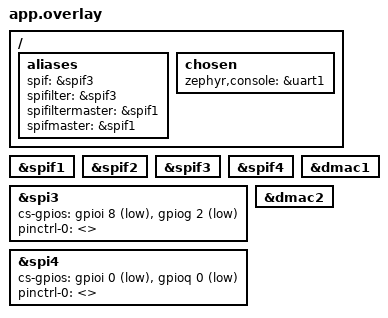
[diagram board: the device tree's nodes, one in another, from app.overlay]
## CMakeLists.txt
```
# SPDX-License-Identifier: Apache-2.0

cmake_minimum_required(VERSION 3.20.0)

# ---------------------------------------------------------------------------
# pfr_tpm 模块注册。
# zephyr/west.yml **并未**注册该模块（`west list` 无此项）。
# app.overlay 的 "lsqsh_pinctrl_pfr_tpm.dtsi" 必须靠这里就地注册，
# 否则 DT 预处理直接失败："fatal error: lsqsh_pinctrl_pfr_tpm.dtsi: No such file or directory"。
# 模块目录在两种工作区里命名不同（zephyr_pfr_tpm / pfr_tpm），按存在者取；
# 旧版本写死 d:/zephyr4_0/... 换工作区/WSL 会失效，故改为相对路径推算
# （CMAKE_CURRENT_SOURCE_DIR 上溯 4 级 = 工作区根）。必须在 find_package(Zephyr) 之前 set。
# ---------------------------------------------------------------------------
get_filename_component(PFR_TPM_WS "${CMAKE_CURRENT_SOURCE_DIR}/../../../.." ABSOLUTE)
if(EXISTS "${PFR_TPM_WS}/modules/lib/zephyr_pfr_tpm/zephyr/module.yml")
  set(PFR_TPM_DIR "${PFR_TPM_WS}/modules/lib/zephyr_pfr_tpm")
elseif(EXISTS "${PFR_TPM_WS}/modules/lib/pfr_tpm/zephyr/module.yml")
  set(PFR_TPM_DIR "${PFR_TPM_WS}/modules/lib/pfr_tpm")
else()
  message(FATAL_ERROR "pfr_tpm module not found under ${PFR_TPM_WS}/modules/lib")
endif()
set(EXTRA_ZEPHYR_MODULES ${PFR_TPM_DIR})

find_package(Zephyr REQUIRED HINTS $ENV{ZEPHYR_BASE})
project(cpu1_spif_test)

# 项目特定源文件
target_sources(app PRIVATE
    src/main.c
    src/spif_test.c
    src/spif_loopback.c)

# 项目特定 include 目录
target_include_directories(app PRIVATE
    ${CMAKE_CURRENT_SOURCE_DIR}/../tests/include)

# 包含公共源文件和配置（test_results.c, ztest_glue.c, gpio_toggle.c）
include(${CMAKE_CURRENT_SOURCE_DIR}/../../../common/common_sources.cmake)
```

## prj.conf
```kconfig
# SPDX-License-Identifier: Apache-2.0
#
# spif_test 单核 cpu1 固件配置（SPEC_REFERENCE §6.1.7 / §6.1.8）。

# ---- log 规范（§6.1.7）：统一 LOG_INF，buf 模式异步输出 ----
CONFIG_LOG=y
CONFIG_LOG_MODE_DEFERRED=y
CONFIG_LOG_BUFFER_SIZE=16384
CONFIG_LOG_PROCESS_THREAD_SLEEP_MS=10
CONFIG_LOG_BACKEND_UART=y
CONFIG_LOG_PRINTK=n
CONFIG_SERIAL=y
CONFIG_SHELL=n

# ---- ztest（§6.2.1）：逐项输出必须打开 ----
CONFIG_ZTEST=y
CONFIG_ZTEST_ASSERT_VERBOSE=1
CONFIG_ZTEST_VERBOSE_OUTPUT=y
CONFIG_ZTEST_SUMMARY=n

# ---- libc 三件套（§10.35 / KNOWN_ISSUES #58）----
CONFIG_PICOLIBC=y
CONFIG_NEWLIB_LIBC=n
CONFIG_MINIMAL_LIBC=n

# ---- GPIO toggle 线程（公共层 gpio_toggle.c 依赖）----
CONFIG_GPIO=y

# ---- 被测驱动：pfr_tpm spi filter ----
# CONFIG_SPI_FILTER_LINKEDSEMI 默认 y（depends on DT_HAS_LINKEDSEMI_SPI_FILTER_ENABLED），
# 且 select SPI / select DMA；CONFIG_PFR_TPM_LINKER_LD 随之 default y
# （模块 common/linker.ld 把各实例的白名单镜像放 PFR_TPM 段，本工程依赖该段）。
CONFIG_SPI=y
CONFIG_SPI_FILTER_LINKEDSEMI=y
CONFIG_DMA=y
```

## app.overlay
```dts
/*
 * SPDX-License-Identifier: Apache-2.0
 *
 * spif_test overlay（单核 cpu1 安全域）：使能 SPIF1..4（SPI filter / monitor）
 * 以及它们配对的 SPI master 控制器（spi1/spif1 用 spi3；spif3/spif4 用 spi4）。
 *
 * 外部条件（SPEC_REFERENCE §6.6）：
 *   - SPIF 的 "in 侧" 管脚（滤波/监视模式的输入，以及 master 模式下 SPI 主控
 *     的 CLK/IO0..3/CSN 输出）在板级连到 **spi3 / spi4 上挂的 flash**。
 *     本工程 master 模式用例（`master_read_jedec_id`）走这条外部路径。
 *   - 其余寄存器级用例零外部条件。
 *
 * ⚠️ 配对控制器必须让渡引脚（P4.7 裁定，依据参考资产 spi_master_communication /
 *    spi_monitor_filter 的 overlay，二者在实机跑通）：
 *    SPIF 切 master 模式走的是 **SPIF 自己的 `pinctrl-2`(master 态)** 管脚
 *    （如 spif3 → PF09/PF05/PF03/PF11/PF07 + CSN PI00），而配对的 DW SPI 控制器
 *    默认仍持板级 pinctrl（spi3 → PG14/PG15/PG03/PE01/PE00；spi4 → PQ00/PQ03…）。
 *    两组管脚不同 ⇒ 不清空配对控制器的 `pinctrl-0` 就是"两个 owner 抢一组 net"，
 *    真实总线由谁驱动不确定。故此处显式清空。
 *    （同型问题见 gotchas G-P4-4「配对 I2C 控制器 pinctrl-noinit」/ G-P4.7-1。）
 */

#include "lsqsh_pinctrl_pfr_tpm.dtsi"

/ {
	aliases {
		/* 回环路径：spif1 发命令/数据，spif3 作 filter/passthrough 监视。
		 * spifmaster/spifiltermaster 都指向 spif1；spif/spifilter 指向 spif3。
		 * 旧的 spifmaster=&spif3 是 spif3-master 用例遗留，已纠正。 */
		spif = &spif3;
		spifilter = &spif3;
		spifiltermaster = &spif1;
		spifmaster = &spif1;
	};

	chosen {
		zephyr,console = &uart1;
	};
};

&spif1 {
	status = "okay";
};

&spif2 {
	status = "okay";
};

&spif3 {
	status = "okay";
};

&spif4 {
	status = "okay";
};

/* CS 数组下标与 SPIF 的 cs-gpios 对应（SPIF3 → CS0 = GPIOI 0） */
&spi3 {
	cs-gpios = <&gpioi 8 GPIO_ACTIVE_LOW>,
		    <&gpiog 2 GPIO_ACTIVE_LOW>;
	/* 引脚让渡给 SPIF master 态（spif1/spif2 的 spi = <&spi3>） */
	pinctrl-0 = <>;
	pinctrl-names = "default";
	status = "okay";
};

&spi4 {
	cs-gpios = <&gpioi 0 GPIO_ACTIVE_LOW>,
		    <&gpioq 0 GPIO_ACTIVE_LOW>;
	/* 引脚让渡给 SPIF master 态（spif3/spif4 的 spi = <&spi4>） */
	pinctrl-0 = <>;
	pinctrl-names = "default";
	status = "okay";
};

&dmac1 {
	status = "okay";
};

&dmac2 {
	status = "okay";
};

/* GPIO toggle 使能块统一走公共层（SPEC_REFERENCE §6.1.9 复用收敛） */
#include "../../../common/gpio_toggle.dtsi"
```

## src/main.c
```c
/*
 * SPDX-License-Identifier: Apache-2.0
 *
 * spif_test 单核测试入口（cpu1 安全域）。
 * 纯 ztest：test_main 打印角色 banner 后 zt_init + zt_run_all
 * （common/ztest_glue），不返回（同 ztest 语义）。
 */

#include <zephyr/kernel.h>
#include <zephyr/device.h>
#include <zephyr/logging/log.h>

#include "ztest_glue.h"

LOG_MODULE_REGISTER(spif_test, LOG_LEVEL_INF);

void test_main(void)
{
	LOG_INF("[CPU1 SPIF] SPI filter test started");   /* 角色 banner（harness 依赖） */

	zt_init("TGT");
	zt_run_all();
}
```

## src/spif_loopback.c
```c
/*
 * SPDX-License-Identifier: Apache-2.0
 *
 * spif_test 回环用例：spif1(master) + spif3(filter/passthrough) -> flash3_0。
 *
 * 参考资产：modules/lib/zephyr_pfr_tpm/samples/spi_monitor_filter/src/main.c
 *   - spif3 置 filter 态、flash_size=MB(32)、filter_enable、passthrough；
 *   - spif1 置 master 态，经其配对 spi3（CS0 = GPIOI 8）发裸 0x9F / 0x03；
 *   - spif3 在 spi4 侧做监视（in 侧外部接到 spif1/spi3 总线）。
 *
 * 本文件只读 flash，不擦写：JEDEC 读用于判定链路真的通了（不是全 0/全 FF），
 * 0x03 读用于覆盖参考资产的带地址命令形态。每项自带 setup/teardown，失败时
 * 也先把 spif1 切回 filter，避免污染后续用例。
 */

#include <zephyr/kernel.h>
#include <zephyr/ztest.h>
#include <zephyr/device.h>
#include <zephyr/drivers/spi.h>
#include <zephyr/drivers/gpio.h>
#include <zephyr/sys/util.h>
#include <zephyr/sys/sys_io.h>
#include <zephyr/logging/log.h>
#include <string.h>

#include "ztest_glue.h"
#include "spif_test.h"

#include <spi_filter.h>

LOG_MODULE_REGISTER(spif_loopback, LOG_LEVEL_INF);

/* 参考资产的实例/地址选择：spif3=filter，spif1=master，flash3_0 在 spi3 CS0 */
#define LOOP_FILTER_IDX 2
#define LOOP_MASTER_IDX 0
#define LOOP_SIBLING_IDX 1
#define LOOP_READ_ADDR 0x4000u
#define LOOP_READ_LEN 8u
#define LOOP_FREQ MHZ(1)

static int loopback_setup(void)
{
	const struct device *filter = spif_dev(LOOP_FILTER_IDX);
	const struct device *master = spif_dev(LOOP_MASTER_IDX);
	const struct device *sibling = spif_dev(LOOP_SIBLING_IDX);
	int ret;

	ret = linkedsemi_spi_filter_cold_reset(filter);
	if (ret != 0) {
		return ret;
	}

	ret = spif_flash_size_set(filter, MB(32));
	if (ret != 0) {
		return ret;
	}

	spif_filter_enable(filter, true);
	if (!spif_pinctrl_filter_mode_check(filter)) {
		return -EIO;
	}

	ret = spif_passthrough_analog_mux_enable(filter, true);
	if (ret != 0) {
		return ret;
	}
	if (!spif_pinctrl_passthrough_mode_check(filter)) {
		return -EIO;
	}

	/* 参考资产只显式放行 0x03；JEDEC 0x9F 不在固定表默认项里，cold_reset
	 * 后其 EN=0，需要显式 add，否则 filter 会把 0x9F 当非法命令。 */
	ret = spif_add_cmd(filter, 0x9f);
	if (ret != 0) {
		return ret;
	}
	ret = spif_add_cmd(filter, 0x03);
	if (ret != 0) {
		return ret;
	}

	/* 参考资产调用 configure_address_protection(DISABLE) 清掉 0x4000..0x8000
	 * 的 allow 位；驱动语义里 DISABLE = 标记为非法，会在 filter 日志里打
	 * ADDR_ERR（流量仍可透传）。本用例验证链路而非保护错误，故显式 ENABLE
	 * 该区间，保持 cold_reset 默认的全片放行语义。 */
	ret = spif_address_privilege_config(filter, FLAG_ADDR_PRIV_READ_SELECT,
					    FLAG_ADDR_PRIV_ENABLE, LOOP_READ_ADDR,
					    KB(16));
	if (ret != 0) {
		return ret;
	}
	ret = spif_address_privilege_config(filter, FLAG_ADDR_PRIV_WRITE_SELECT,
					    FLAG_ADDR_PRIV_ENABLE, LOOP_READ_ADDR,
					    KB(16));
	if (ret != 0) {
		return ret;
	}

	/* spif1 的相邻实例 spif2 必须先回 filter，否则 master 切换 -EBUSY */
	ret = spif_switch_to_filter(sibling);
	if (ret != 0) {
		return ret;
	}
	ret = spif_switch_to_master(master);
	if (ret != 0) {
		return ret;
	}
	if (!spif_pinctrl_master_mode_check(master)) {
		return -EIO;
	}

	return 0;
}

static void loopback_teardown(void)
{
	(void)spif_switch_to_filter(spif_dev(LOOP_MASTER_IDX));
	(void)spif_remove_cmd(spif_dev(LOOP_FILTER_IDX), 0x9f);
	(void)spif_remove_cmd(spif_dev(LOOP_FILTER_IDX), 0x03);
	(void)spif_switch_to_filter(spif_dev(LOOP_FILTER_IDX));
}

static int loopback_xfer(const uint8_t *tx, size_t tx_len, uint8_t *rx, size_t rx_len)
{
	const struct device *master = spif_dev(LOOP_MASTER_IDX);
	const struct device *spi = spif_spi_dev(master);
	const struct spi_config cfg = {
		.operation = SPI_OP_MODE_MASTER | SPI_WORD_SET(8) | SPI_TRANSFER_MSB,
		.frequency = LOOP_FREQ,
		.cs = { .gpio = *(spif_spi_cs(master)) },
	};
	const struct spi_buf tx_buf = { .buf = (void *)tx, .len = tx_len };
	const struct spi_buf_set tx_set = { .buffers = &tx_buf, .count = 1 };
	struct spi_buf rx_buf = { .buf = rx, .len = rx_len };
	const struct spi_buf_set rx_set = { .buffers = &rx_buf, .count = 1 };

	if (!device_is_ready(spi)) {
		return -ENODEV;
	}

	memset(rx, 0, rx_len);
	return spi_transceive(spi, &cfg, &tx_set, &rx_set);
}

ZTEST(spif, loopback_jedec)
{
	static const uint8_t tx[] = { 0x9f };
	uint8_t rx[4] = { 0 };
	int ret;

	ret = loopback_setup();
	if (ret == 0) {
		ret = loopback_xfer(tx, sizeof(tx), rx, sizeof(rx));
	}
	loopback_teardown();

	ZT_INFO("loopback_jedec", "ret=%d,jedec=%02x%02x%02x", ret, rx[1], rx[2], rx[3]);
	zassert_ok(ret, "spif1 master JEDEC transceive failed (ret=%d)", ret);

	/* 空总线读回常是全 0 或全 FF；真实 NOR 的 JEDEC 不会两者都命中。 */
	zassert_false(rx[1] == 0x00 && rx[2] == 0x00 && rx[3] == 0x00,
		      "JEDEC read all zero (no flash / link down)");
	zassert_false(rx[1] == 0xff && rx[2] == 0xff && rx[3] == 0xff,
		      "JEDEC read all 0xff (no flash / link down)");
}

ZTEST(spif, loopback_read_addr)
{
	static const uint8_t tx[] = { 0x03, 0x00, 0x40, 0x00 }; /* 0x004000 */
	uint8_t rx[4 + LOOP_READ_LEN] = { 0 };
	int ret;

	ret = loopback_setup();
	if (ret == 0) {
		ret = loopback_xfer(tx, sizeof(tx), rx, sizeof(rx));
	}
	loopback_teardown();

	ZT_INFO("loopback_read_addr", "ret=%d,data=%02x%02x%02x%02x", ret, rx[4], rx[5],
		rx[6], rx[7]);
	zassert_ok(ret, "spif1 master 0x03 read transceive failed (ret=%d)", ret);
}

/*
 * 过滤矩阵：命令/地址 合法 × 合法/非法 四种组合。
 *
 * 驱动/HW 语义（用户 2026-10-29 明确）：
 *   命令合法 + 地址合法 → 无 ERROR
 *   命令合法 + 地址非法 → ADDR_ERR=1，CMD_ERR=0，ERROR_CMD=命令值，ERROR_ADDR=地址
 *   命令非法 + 地址合法 → CMD_ERR=1，ADDR_ERR=0，ERROR_CMD=命令值
 *   命令非法 + 地址非法 → CMD_ERR=1，ADDR_ERR=0（先查命令，命中即上报）
 *
 * 每项都从 loopback_setup() 的 cold_reset 开始，确保 SPIF_DMA_DATA 无上一项残留；
 * 结束后 teardown 恢复 master/filter 与命令表。
 */
static int loopback_filter_run(bool cmd_legal, bool addr_legal,
			       spif_dma_data_t *before, spif_dma_data_t *err)
{
	const struct device *filter = spif_dev(LOOP_FILTER_IDX);
	const uintptr_t base = spif_reg_base(LOOP_FILTER_IDX);
	static const uint8_t tx[] = { 0x03, 0x00, 0x40, 0x00 };
	uint8_t rx[4 + LOOP_READ_LEN] = { 0 };
	int ret;

	err->value = 0;
	before->value = 0;
	ret = loopback_setup();

	if (ret == 0 && !cmd_legal) {
		/* 只移 0x03：0x9F 仍在白名单，确保是命令过滤而不是链路断 */
		ret = spif_remove_cmd(filter, 0x03);
	}
	if (ret == 0 && !addr_legal) {
		/* cold_reset 默认全片 allow；清掉 0x4000..0x8000 的读 allow 位 */
		ret = spif_address_privilege_config(filter, FLAG_ADDR_PRIV_READ_SELECT,
						    FLAG_ADDR_PRIV_DISABLE, LOOP_READ_ADDR,
						    KB(16));
	}
	if (ret == 0) {
		spif_intr_clr_t clr = {
			.ERROR = 1,
			.ERROR_OVERFLOW = 1,
			.BITMAP = 1,
		};

		/* 读前快照：cold_reset 后 SPIF_DMA_DATA 必须为 0，排除陈旧值假 PASS */
		before->value = sys_read32(base + SPIF_DMA_DATA);
		sys_write32(clr.value, base + SPIF_INTR_CLR);
		ret = loopback_xfer(tx, sizeof(tx), rx, sizeof(rx));
		k_msleep(5);   /* 等 filter ISR 采样 SPIF_DMA_DATA */
		err->value = sys_read32(base + SPIF_DMA_DATA);
	}

	loopback_teardown();
	return ret;
}

ZTEST(spif, loopback_filter_legal_both)
{
	spif_dma_data_t before = { 0 };
	spif_dma_data_t err = { 0 };
	int ret = loopback_filter_run(true, true, &before, &err);

	ZT_INFO("loopback_filter_legal_both",
		"before=%#x,ret=%d,raw=%#x,cmd_err=%d,addr_err=%d,por_addr=%d,error_cmd=%#x,error_addr=%#x",
		before.value, ret, err.value, err.CMD_ERR, err.ADDR_ERR, err.POR_ADDR,
		err.ERROR_CMD, err.ERROR_ADDR << 11);
	zassert_equal(before.value, 0, "SPIF_DMA_DATA must be clean after cold_reset");
	zassert_ok(ret, "legal cmd + legal addr transceive failed (ret=%d)", ret);
	zassert_equal(err.CMD_ERR, 0, "legal cmd must not set CMD_ERR");
	zassert_equal(err.ADDR_ERR, 0, "legal addr must not set ADDR_ERR");
	zassert_equal(err.POR_ADDR, 0, "no POR_ADDR expected");
	zassert_equal(err.ERROR_CMD, 0, "no ERROR_CMD expected");
	zassert_equal(err.ERROR_ADDR, 0, "no ERROR_ADDR expected");
}

ZTEST(spif, loopback_filter_legal_cmd_bad_addr)
{
	spif_dma_data_t before = { 0 };
	spif_dma_data_t err = { 0 };
	int ret = loopback_filter_run(true, false, &before, &err);

	ZT_INFO("loopback_filter_legal_cmd_bad_addr",
		"before=%#x,ret=%d,raw=%#x,cmd_err=%d,addr_err=%d,por_addr=%d,error_cmd=%#x,error_addr=%#x",
		before.value, ret, err.value, err.CMD_ERR, err.ADDR_ERR, err.POR_ADDR,
		err.ERROR_CMD, err.ERROR_ADDR << 11);
	zassert_equal(before.value, 0, "SPIF_DMA_DATA must be clean after cold_reset");
	zassert_ok(ret, "legal cmd + bad addr transceive failed (ret=%d)", ret);
	zassert_equal(err.CMD_ERR, 0, "legal cmd must not set CMD_ERR");
	zassert_equal(err.ADDR_ERR, 1, "bad addr must set ADDR_ERR");
	zassert_equal(err.POR_ADDR, 1, "read-address rejection must set POR_ADDR");
	zassert_equal(err.ERROR_CMD, 0x03, "ERROR_CMD must hold the legal command");
	zassert_equal(err.ERROR_ADDR << 11, LOOP_READ_ADDR,
		      "ERROR_ADDR must hold the blocked address");
}

ZTEST(spif, loopback_filter_bad_cmd_legal_addr)
{
	spif_dma_data_t before = { 0 };
	spif_dma_data_t err = { 0 };
	int ret = loopback_filter_run(false, true, &before, &err);

	ZT_INFO("loopback_filter_bad_cmd_legal_addr",
		"before=%#x,ret=%d,raw=%#x,cmd_err=%d,addr_err=%d,por_addr=%d,error_cmd=%#x,error_addr=%#x",
		before.value, ret, err.value, err.CMD_ERR, err.ADDR_ERR, err.POR_ADDR,
		err.ERROR_CMD, err.ERROR_ADDR << 11);
	zassert_equal(before.value, 0, "SPIF_DMA_DATA must be clean after cold_reset");
	zassert_ok(ret, "bad cmd + legal addr transceive failed (ret=%d)", ret);
	zassert_equal(err.CMD_ERR, 1, "bad cmd must set CMD_ERR");
	zassert_equal(err.ADDR_ERR, 0, "legal addr must not set ADDR_ERR");
	zassert_equal(err.POR_ADDR, 0, "no POR_ADDR on command error");
	zassert_equal(err.ERROR_CMD, 0x03, "ERROR_CMD must hold the blocked command");
	zassert_equal(err.ERROR_ADDR, 0, "ERROR_ADDR must be 0 when only cmd fails");
}

ZTEST(spif, loopback_filter_bad_cmd_bad_addr)
{
	spif_dma_data_t before = { 0 };
	spif_dma_data_t err = { 0 };
	int ret = loopback_filter_run(false, false, &before, &err);

	ZT_INFO("loopback_filter_bad_cmd_bad_addr",
		"before=%#x,ret=%d,raw=%#x,cmd_err=%d,addr_err=%d,por_addr=%d,error_cmd=%#x,error_addr=%#x",
		before.value, ret, err.value, err.CMD_ERR, err.ADDR_ERR, err.POR_ADDR,
		err.ERROR_CMD, err.ERROR_ADDR << 11);
	zassert_equal(before.value, 0, "SPIF_DMA_DATA must be clean after cold_reset");
	zassert_ok(ret, "bad cmd + bad addr transceive failed (ret=%d)", ret);
	zassert_equal(err.CMD_ERR, 1, "bad cmd must set CMD_ERR");
	/* 命令先查，命中后不再上报地址错误 */
	zassert_equal(err.ADDR_ERR, 0, "addr must not be checked after bad cmd");
	zassert_equal(err.POR_ADDR, 0, "no POR_ADDR after command-first rejection");
	zassert_equal(err.ERROR_CMD, 0x03, "ERROR_CMD must hold the blocked command");
	zassert_equal(err.ERROR_ADDR, 0, "ERROR_ADDR must be 0 after command-first rejection");
}
```

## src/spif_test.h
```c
/*
 * SPDX-License-Identifier: Apache-2.0
 *
 * spif_test 公共定义（单核 cpu1）。
 * 覆盖矩阵见 tests/COVERAGE.md。
 */

#ifndef SPIF_TEST_H_
#define SPIF_TEST_H_

#include <zephyr/device.h>
#include <stdint.h>

/* 被测实例数（spif1..spif4，overlay 全使能） */
#define SPIF_INST_NUM 4

/* idx 0..3 → spif1..spif4（DT index 属性同序）；越界返回 NULL */
const struct device *spif_dev(int idx);

/* idx 0..3 → spifN 寄存器基址；越界返回 0 */
uintptr_t spif_reg_base(int idx);

#endif /* SPIF_TEST_H_ */
```
